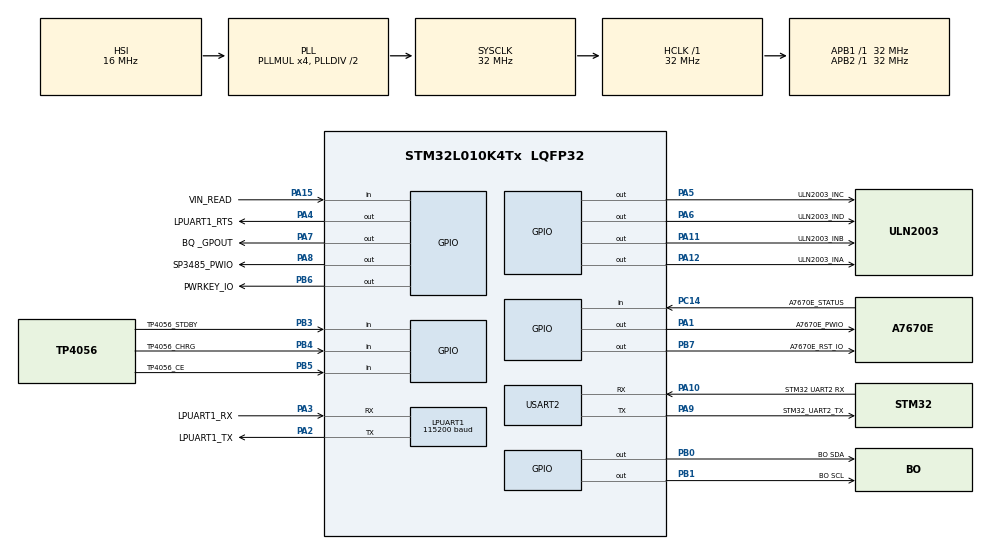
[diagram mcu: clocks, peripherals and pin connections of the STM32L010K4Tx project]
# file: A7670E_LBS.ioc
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LPUART1.BaudRate=115200
LPUART1.WordLength=UART_WORDLENGTH_8B
Mcu.Family=STM32L0
Mcu.Name=STM32L010K4Tx
Mcu.Package=LQFP32
NVIC.LPUART1_IRQn=true\:0\:0\:false\:false\:true\:true\:true\:true
NVIC.RTC_IRQn=true\:0\:0\:false\:false\:true\:true\:true\:true
NVIC.TIM2_IRQn=true\:0\:0\:false\:false\:true\:true\:true\:true
NVIC.USART2_IRQn=true\:0\:0\:false\:false\:true\:true\:true\:true
PA1.GPIO_Label=A7670E_PWIO
PA1.Signal=GPIO_Output
PA10.GPIO_Label=STM32 UART2 RX
PA10.Mode=Asynchronous
PA10.Signal=USART2_RX
PA11.GPIO_Label=ULN2003_INB
PA11.Signal=GPIO_Output
PA12.GPIO_Label=ULN2003_INA
PA12.Signal=GPIO_Output
PA13.Mode=Serial_Wire
PA13.Signal=SYS_SWDIO
PA14.Mode=Serial_Wire
PA14.Signal=SYS_SWCLK
PA15.GPIO_Label=VIN_READ
PA15.Signal=GPIO_Input
PA2.GPIO_Label=LPUART1_TX
PA2.Mode=Asynchronous
PA2.Signal=LPUART1_TX
PA3.GPIO_Label=LPUART1_RX
PA3.Mode=Asynchronous
PA3.Signal=LPUART1_RX
PA4.GPIO_Label=LPUART1_RTS
PA4.Signal=GPIO_Output
PA5.GPIO_Label=ULN2003_INC
PA5.Signal=GPIO_Output
PA6.GPIO_Label=ULN2003_IND
PA6.Signal=GPIO_Output
PA7.GPIO_Label=BQ _GPOUT
PA7.Signal=GPIO_Output
PA8.GPIO_Label=SP3485_PWIO
PA8.Signal=GPIO_Output
PA9.GPIO_Label=STM32_UART2_TX
PA9.Mode=Asynchronous
PA9.Signal=USART2_TX
PB0.GPIO_Label=BO SDA
PB0.Signal=GPIO_Output
PB1.GPIO_Label=BO SCL
PB1.Signal=GPIO_Output
PB3.GPIO_Label=TP4056_STDBY
PB3.Signal=GPIO_Input
PB4.GPIO_Label=TP4056_CHRG
PB4.Signal=GPIO_Input
PB5.GPIO_Label=TP4056_CE
PB5.Signal=GPIO_Input
PB6.GPIO_Label=PWRKEY_IO
PB6.Signal=GPIO_Output
PB7.GPIO_Label=A7670E_RST_IO
PB7.Signal=GPIO_Output
PC14-OSC32_IN.GPIO_Label=A7670E_STATUS
PC14-OSC32_IN.Signal=GPIO_Input
ProjectManager.HeapSize=0x50
ProjectManager.StackSize=0x100
ProjectManager.TargetToolchain=MDK-ARM V5.32
RCC.AHBFreq_Value=32000000
RCC.APB1Freq_Value=32000000
RCC.APB1TimFreq_Value=32000000
RCC.APB2Freq_Value=32000000
RCC.APB2TimFreq_Value=32000000
RCC.HCLKFreq_Value=32000000
RCC.HSE_VALUE=8000000
RCC.HSI16_VALUE=16000000
RCC.HSI_VALUE=16000000
RCC.LSE_VALUE=32768
RCC.MSI_VALUE=2097000
RCC.PLLMUL=RCC_PLLMUL_4
RCC.SYSCLKFreq_VALUE=32000000
RCC.SYSCLKSource=RCC_SYSCLKSOURCE_PLLCLK
RCC.VCOOutputFreq_Value=64000000
RTC.Alarm-Alarm\ A=RTC_ALARM_A
RTC.AlarmMaskMinutes-Alarm\ A=RTC_ALARMMASK_MINUTES
RTC.AsynchPrediv=124
RTC.Minutes_A-Alarm\ A=30
RTC.SynchPrediv=295
TIM2.AutoReloadPreload=TIM_AUTORELOAD_PRELOAD_ENABLE
TIM2.Period=10000
TIM2.Prescaler=3200-1
USART2.VirtualMode=VM_ASYNC
VP_RTC_VS_RTC_Activate.Mode=RTC_Enabled
VP_RTC_VS_RTC_Alarm_A_Intern.Mode=Alarm A
VP_RTC_VS_RTC_Calendar.Mode=RTC_Calendar
VP_TIM2_VS_ClockSourceINT.Mode=Internal
board=custom

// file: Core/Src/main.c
/* USER CODE BEGIN Header */
/**
  ******************************************************************************
  * @file           : main.c
  * @brief          : Main program body
  ******************************************************************************
  * @attention
  *
  * Copyright (c) 2024 STMicroelectronics.
  * All rights reserved.
  *
  * This software is licensed under terms that can be found in the LICENSE file
  * in the root directory of this software component.
  * If no LICENSE file comes with this software, it is provided AS-IS.
  *
  ******************************************************************************
  */
/* USER CODE END Header */
#include "main.h"
#include "usart.h"
#include "rtc.h"
#include "tim.h"
#include "gpio.h"

/* USER CODE BEGIN Includes */
#include "battery.h"
#include "positionmodule.h"
#include "steppermotor.h"

#include "bq27220.h"
/* USER CODE END Includes */

void SystemClock_Config(void);

int main(void)
{

  /* MCU Configuration--------------------------------------------------------*/

  /* Reset of all peripherals, Initializes the Flash interface and the Systick. */
  HAL_Init();

  /* Configure the system clock */
  SystemClock_Config();

  /* Initialize all configured peripherals */
  MX_GPIO_Init();
  MX_LPUART1_UART_Init();
  MX_USART2_UART_Init();
  MX_RTC_Init();
  MX_TIM2_Init();
  /* USER CODE BEGIN 2 */
    //stepmotor_Init((uintptr_t)&tSteppermotor, (uintptr_t)&tSteppermotorCfg);
  bq27220_t sbq27220;

  sbq27220.pfinit(&sbq27220,NULL,NULL,NULL,NULL,NULL);

  /* USER CODE END 2 */

  /* Infinite loop */
    while (1)
    {

    }
}

void SystemClock_Config(void)
{
  RCC_OscInitTypeDef RCC_OscInitStruct = {0};
  RCC_ClkInitTypeDef RCC_ClkInitStruct = {0};
  RCC_PeriphCLKInitTypeDef PeriphClkInit = {0};

  /** Configure the main internal regulator output voltage
  */
  __HAL_PWR_VOLTAGESCALING_CONFIG(PWR_REGULATOR_VOLTAGE_SCALE1);

  /** Initializes the RCC Oscillators according to the specified parameters
  * in the RCC_OscInitTypeDef structure.
  */
  RCC_OscInitStruct.OscillatorType = RCC_OSCILLATORTYPE_HSI|RCC_OSCILLATORTYPE_LSI;
  RCC_OscInitStruct.HSIState = RCC_HSI_ON;
  RCC_OscInitStruct.HSICalibrationValue = RCC_HSICALIBRATION_DEFAULT;
  RCC_OscInitStruct.LSIState = RCC_LSI_ON;
  RCC_OscInitStruct.PLL.PLLState = RCC_PLL_ON;
  RCC_OscInitStruct.PLL.PLLSource = RCC_PLLSOURCE_HSI;
  RCC_OscInitStruct.PLL.PLLMUL = RCC_PLLMUL_4;
  RCC_OscInitStruct.PLL.PLLDIV = RCC_PLLDIV_2;
  if (HAL_RCC_OscConfig(&RCC_OscInitStruct) != HAL_OK)
  {
    Error_Handler();
  }

  /** Initializes the CPU, AHB and APB buses clocks
  */
  RCC_ClkInitStruct.ClockType = RCC_CLOCKTYPE_HCLK|RCC_CLOCKTYPE_SYSCLK
                              |RCC_CLOCKTYPE_PCLK1|RCC_CLOCKTYPE_PCLK2;
  RCC_ClkInitStruct.SYSCLKSource = RCC_SYSCLKSOURCE_PLLCLK;
  RCC_ClkInitStruct.AHBCLKDivider = RCC_SYSCLK_DIV1;
  RCC_ClkInitStruct.APB1CLKDivider = RCC_HCLK_DIV1;
  RCC_ClkInitStruct.APB2CLKDivider = RCC_HCLK_DIV1;

  if (HAL_RCC_ClockConfig(&RCC_ClkInitStruct, FLASH_LATENCY_1) != HAL_OK)
  {
    Error_Handler();
  }
  PeriphClkInit.PeriphClockSelection = RCC_PERIPHCLK_USART2|RCC_PERIPHCLK_LPUART1
                              |RCC_PERIPHCLK_RTC;
  PeriphClkInit.Usart2ClockSelection = RCC_USART2CLKSOURCE_PCLK1;
  PeriphClkInit.Lpuart1ClockSelection = RCC_LPUART1CLKSOURCE_PCLK1;
  PeriphClkInit.RTCClockSelection = RCC_RTCCLKSOURCE_LSI;
  if (HAL_RCCEx_PeriphCLKConfig(&PeriphClkInit) != HAL_OK)
  {
    Error_Handler();
  }
}

void Error_Handler(void)
{
    __disable_irq();
    while (1)
    {
    }
}
